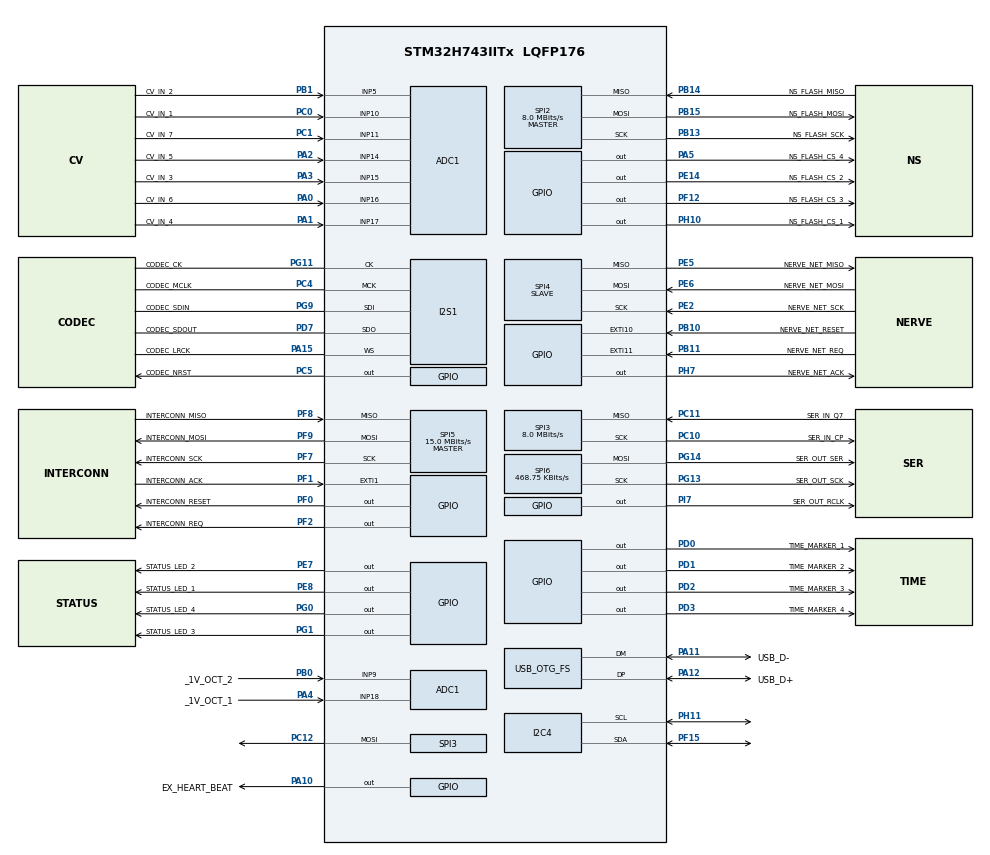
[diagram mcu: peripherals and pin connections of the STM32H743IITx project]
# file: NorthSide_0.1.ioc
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ADC1.Channel-10\#ChannelRegularConversion=ADC_CHANNEL_5
ADC1.Channel-11\#ChannelRegularConversion=ADC_CHANNEL_15
ADC1.Channel-12\#ChannelRegularConversion=ADC_CHANNEL_17
ADC1.Channel-13\#ChannelRegularConversion=ADC_CHANNEL_14
ADC1.Channel-14\#ChannelRegularConversion=ADC_CHANNEL_16
ADC1.Channel-16\#ChannelRegularConversion=ADC_CHANNEL_11
ADC1.Channel-7\#ChannelRegularConversion=ADC_CHANNEL_18
ADC1.Channel-8\#ChannelRegularConversion=ADC_CHANNEL_9
ADC1.Channel-9\#ChannelRegularConversion=ADC_CHANNEL_10
ADC1.ClockPrescaler=ADC_CLOCK_ASYNC_DIV8
ADC1.NbrOfConversion=9
ADC1.NbrOfConversionFlag=1
ADC1.OffsetNumber-10\#ChannelRegularConversion=ADC_OFFSET_NONE
ADC1.OffsetNumber-11\#ChannelRegularConversion=ADC_OFFSET_NONE
ADC1.OffsetNumber-12\#ChannelRegularConversion=ADC_OFFSET_NONE
ADC1.OffsetNumber-13\#ChannelRegularConversion=ADC_OFFSET_NONE
ADC1.OffsetNumber-14\#ChannelRegularConversion=ADC_OFFSET_NONE
ADC1.OffsetNumber-16\#ChannelRegularConversion=ADC_OFFSET_NONE
ADC1.OffsetNumber-7\#ChannelRegularConversion=ADC_OFFSET_NONE
ADC1.OffsetNumber-8\#ChannelRegularConversion=ADC_OFFSET_NONE
ADC1.OffsetNumber-9\#ChannelRegularConversion=ADC_OFFSET_NONE
ADC1.OffsetSignedSaturation-10\#ChannelRegularConversion=DISABLE
ADC1.OffsetSignedSaturation-11\#ChannelRegularConversion=DISABLE
ADC1.OffsetSignedSaturation-12\#ChannelRegularConversion=DISABLE
ADC1.OffsetSignedSaturation-13\#ChannelRegularConversion=DISABLE
ADC1.OffsetSignedSaturation-14\#ChannelRegularConversion=DISABLE
ADC1.OffsetSignedSaturation-16\#ChannelRegularConversion=DISABLE
ADC1.OffsetSignedSaturation-7\#ChannelRegularConversion=DISABLE
ADC1.OffsetSignedSaturation-8\#ChannelRegularConversion=DISABLE
ADC1.OffsetSignedSaturation-9\#ChannelRegularConversion=DISABLE
ADC1.Rank-10\#ChannelRegularConversion=4
ADC1.Rank-11\#ChannelRegularConversion=5
ADC1.Rank-12\#ChannelRegularConversion=6
ADC1.Rank-13\#ChannelRegularConversion=7
ADC1.Rank-14\#ChannelRegularConversion=8
ADC1.Rank-16\#ChannelRegularConversion=9
ADC1.Rank-7\#ChannelRegularConversion=1
ADC1.Rank-8\#ChannelRegularConversion=2
ADC1.Rank-9\#ChannelRegularConversion=3
ADC1.SamplingTime-10\#ChannelRegularConversion=ADC_SAMPLETIME_16CYCLES_5
ADC1.SamplingTime-11\#ChannelRegularConversion=ADC_SAMPLETIME_16CYCLES_5
ADC1.SamplingTime-12\#ChannelRegularConversion=ADC_SAMPLETIME_16CYCLES_5
ADC1.SamplingTime-13\#ChannelRegularConversion=ADC_SAMPLETIME_16CYCLES_5
ADC1.SamplingTime-14\#ChannelRegularConversion=ADC_SAMPLETIME_16CYCLES_5
ADC1.SamplingTime-16\#ChannelRegularConversion=ADC_SAMPLETIME_16CYCLES_5
ADC1.SamplingTime-7\#ChannelRegularConversion=ADC_SAMPLETIME_16CYCLES_5
ADC1.SamplingTime-8\#ChannelRegularConversion=ADC_SAMPLETIME_16CYCLES_5
ADC1.SamplingTime-9\#ChannelRegularConversion=ADC_SAMPLETIME_16CYCLES_5
ADC1.master=1
Bdma.Request0=SPI6_TX
Bdma.RequestsNb=1
Bdma.SPI6_TX.0.Direction=DMA_MEMORY_TO_PERIPH
Bdma.SPI6_TX.0.EventEnable=DISABLE
Bdma.SPI6_TX.0.Instance=BDMA_Channel0
Bdma.SPI6_TX.0.MemDataAlignment=DMA_MDATAALIGN_BYTE
Bdma.SPI6_TX.0.MemInc=DMA_MINC_ENABLE
Bdma.SPI6_TX.0.Mode=DMA_NORMAL
Bdma.SPI6_TX.0.PeriphDataAlignment=DMA_PDATAALIGN_BYTE
Bdma.SPI6_TX.0.PeriphInc=DMA_PINC_DISABLE
Bdma.SPI6_TX.0.Polarity=HAL_DMAMUX_REQ_GEN_RISING
Bdma.SPI6_TX.0.Priority=DMA_PRIORITY_LOW
Bdma.SPI6_TX.0.RequestNumber=1
Bdma.SPI6_TX.0.SignalID=NONE
Bdma.SPI6_TX.0.SyncEnable=DISABLE
Bdma.SPI6_TX.0.SyncPolarity=HAL_DMAMUX_SYNC_NO_EVENT
Bdma.SPI6_TX.0.SyncRequestNumber=1
Bdma.SPI6_TX.0.SyncSignalID=NONE
CORTEX_M7.AccessPermission_Spec=MPU_REGION_FULL_ACCESS
CORTEX_M7.BaseAddress_Spec=0x30000000
CORTEX_M7.CPU_DCache=Disabled
CORTEX_M7.CPU_ICache=Disabled
CORTEX_M7.Size_Spec=MPU_REGION_SIZE_256KB
CORTEX_M7.default_mode_Activation=1
Dma.ADC1.4.Direction=DMA_PERIPH_TO_MEMORY
Dma.ADC1.4.EventEnable=DISABLE
Dma.ADC1.4.FIFOMode=DMA_FIFOMODE_DISABLE
Dma.ADC1.4.Instance=DMA1_Stream2
Dma.ADC1.4.MemDataAlignment=DMA_MDATAALIGN_HALFWORD
Dma.ADC1.4.MemInc=DMA_MINC_ENABLE
Dma.ADC1.4.Mode=DMA_NORMAL
Dma.ADC1.4.PeriphDataAlignment=DMA_PDATAALIGN_HALFWORD
Dma.ADC1.4.PeriphInc=DMA_PINC_DISABLE
Dma.ADC1.4.Polarity=HAL_DMAMUX_REQ_GEN_RISING
Dma.ADC1.4.Priority=DMA_PRIORITY_LOW
Dma.ADC1.4.RequestNumber=1
Dma.ADC1.4.SignalID=NONE
Dma.ADC1.4.SyncEnable=DISABLE
Dma.ADC1.4.SyncPolarity=HAL_DMAMUX_SYNC_NO_EVENT
Dma.ADC1.4.SyncRequestNumber=1
Dma.ADC1.4.SyncSignalID=NONE
Dma.Request0=SPI5_RX
Dma.Request1=SPI5_TX
Dma.Request2=SPI1_RX
Dma.Request3=SPI1_TX
Dma.Request4=ADC1
Dma.Request5=SPI4_RX
Dma.Request6=SPI4_TX
Dma.SPI1_RX.2.Direction=DMA_PERIPH_TO_MEMORY
Dma.SPI1_RX.2.EventEnable=DISABLE
Dma.SPI1_RX.2.FIFOMode=DMA_FIFOMODE_DISABLE
Dma.SPI1_RX.2.Instance=DMA1_Stream3
Dma.SPI1_RX.2.MemDataAlignment=DMA_MDATAALIGN_WORD
Dma.SPI1_RX.2.MemInc=DMA_MINC_ENABLE
Dma.SPI1_RX.2.Mode=DMA_CIRCULAR
Dma.SPI1_RX.2.PeriphDataAlignment=DMA_PDATAALIGN_WORD
Dma.SPI1_RX.2.PeriphInc=DMA_PINC_DISABLE
Dma.SPI1_RX.2.Polarity=HAL_DMAMUX_REQ_GEN_RISING
Dma.SPI1_RX.2.Priority=DMA_PRIORITY_LOW
Dma.SPI1_RX.2.RequestNumber=1
Dma.SPI1_RX.2.SignalID=NONE
Dma.SPI1_RX.2.SyncEnable=DISABLE
Dma.SPI1_RX.2.SyncPolarity=HAL_DMAMUX_SYNC_NO_EVENT
Dma.SPI1_RX.2.SyncRequestNumber=1
Dma.SPI1_RX.2.SyncSignalID=NONE
Dma.SPI1_TX.3.Direction=DMA_MEMORY_TO_PERIPH
Dma.SPI1_TX.3.EventEnable=DISABLE
Dma.SPI1_TX.3.FIFOMode=DMA_FIFOMODE_DISABLE
Dma.SPI1_TX.3.Instance=DMA1_Stream4
Dma.SPI1_TX.3.MemDataAlignment=DMA_MDATAALIGN_WORD
Dma.SPI1_TX.3.MemInc=DMA_MINC_ENABLE
Dma.SPI1_TX.3.Mode=DMA_CIRCULAR
Dma.SPI1_TX.3.PeriphDataAlignment=DMA_PDATAALIGN_WORD
Dma.SPI1_TX.3.PeriphInc=DMA_PINC_DISABLE
Dma.SPI1_TX.3.Polarity=HAL_DMAMUX_REQ_GEN_RISING
Dma.SPI1_TX.3.Priority=DMA_PRIORITY_LOW
Dma.SPI1_TX.3.RequestNumber=1
Dma.SPI1_TX.3.SignalID=NONE
Dma.SPI1_TX.3.SyncEnable=DISABLE
Dma.SPI1_TX.3.SyncPolarity=HAL_DMAMUX_SYNC_NO_EVENT
Dma.SPI1_TX.3.SyncRequestNumber=1
Dma.SPI1_TX.3.SyncSignalID=NONE
Dma.SPI4_RX.5.Direction=DMA_PERIPH_TO_MEMORY
Dma.SPI4_RX.5.EventEnable=DISABLE
Dma.SPI4_RX.5.FIFOMode=DMA_FIFOMODE_DISABLE
Dma.SPI4_RX.5.Instance=DMA1_Stream5
Dma.SPI4_RX.5.MemDataAlignment=DMA_MDATAALIGN_BYTE
Dma.SPI4_RX.5.MemInc=DMA_MINC_ENABLE
Dma.SPI4_RX.5.Mode=DMA_NORMAL
Dma.SPI4_RX.5.PeriphDataAlignment=DMA_PDATAALIGN_BYTE
Dma.SPI4_RX.5.PeriphInc=DMA_PINC_DISABLE
Dma.SPI4_RX.5.Polarity=HAL_DMAMUX_REQ_GEN_RISING
Dma.SPI4_RX.5.Priority=DMA_PRIORITY_LOW
Dma.SPI4_RX.5.RequestNumber=1
Dma.SPI4_RX.5.SignalID=NONE
Dma.SPI4_RX.5.SyncEnable=DISABLE
Dma.SPI4_RX.5.SyncPolarity=HAL_DMAMUX_SYNC_NO_EVENT
Dma.SPI4_RX.5.SyncRequestNumber=1
Dma.SPI4_RX.5.SyncSignalID=NONE
Dma.SPI4_TX.6.Direction=DMA_MEMORY_TO_PERIPH
Dma.SPI4_TX.6.EventEnable=DISABLE
Dma.SPI4_TX.6.FIFOMode=DMA_FIFOMODE_DISABLE
Dma.SPI4_TX.6.Instance=DMA1_Stream6
Dma.SPI4_TX.6.MemDataAlignment=DMA_MDATAALIGN_BYTE
Dma.SPI4_TX.6.MemInc=DMA_MINC_ENABLE
Dma.SPI4_TX.6.Mode=DMA_NORMAL
Dma.SPI4_TX.6.PeriphDataAlignment=DMA_PDATAALIGN_BYTE
Dma.SPI4_TX.6.PeriphInc=DMA_PINC_DISABLE
Dma.SPI4_TX.6.Polarity=HAL_DMAMUX_REQ_GEN_RISING
Dma.SPI4_TX.6.Priority=DMA_PRIORITY_LOW
Dma.SPI4_TX.6.RequestNumber=1
Dma.SPI4_TX.6.SignalID=NONE
Dma.SPI4_TX.6.SyncEnable=DISABLE
Dma.SPI4_TX.6.SyncPolarity=HAL_DMAMUX_SYNC_NO_EVENT
Dma.SPI4_TX.6.SyncRequestNumber=1
Dma.SPI4_TX.6.SyncSignalID=NONE
Dma.SPI5_RX.0.Direction=DMA_PERIPH_TO_MEMORY
Dma.SPI5_RX.0.EventEnable=DISABLE
Dma.SPI5_RX.0.FIFOMode=DMA_FIFOMODE_DISABLE
Dma.SPI5_RX.0.Instance=DMA1_Stream0
Dma.SPI5_RX.0.MemDataAlignment=DMA_MDATAALIGN_BYTE
Dma.SPI5_RX.0.MemInc=DMA_MINC_ENABLE
Dma.SPI5_RX.0.Mode=DMA_NORMAL
Dma.SPI5_RX.0.PeriphDataAlignment=DMA_PDATAALIGN_BYTE
Dma.SPI5_RX.0.PeriphInc=DMA_PINC_DISABLE
Dma.SPI5_RX.0.Polarity=HAL_DMAMUX_REQ_GEN_RISING
Dma.SPI5_RX.0.Priority=DMA_PRIORITY_LOW
Dma.SPI5_RX.0.RequestNumber=1
Dma.SPI5_RX.0.SignalID=NONE
Dma.SPI5_RX.0.SyncEnable=DISABLE
Dma.SPI5_RX.0.SyncPolarity=HAL_DMAMUX_SYNC_NO_EVENT
Dma.SPI5_RX.0.SyncRequestNumber=1
Dma.SPI5_RX.0.SyncSignalID=NONE
Dma.SPI5_TX.1.Direction=DMA_MEMORY_TO_PERIPH
Dma.SPI5_TX.1.EventEnable=DISABLE
Dma.SPI5_TX.1.FIFOMode=DMA_FIFOMODE_DISABLE
Dma.SPI5_TX.1.Instance=DMA1_Stream1
Dma.SPI5_TX.1.MemDataAlignment=DMA_MDATAALIGN_BYTE
Dma.SPI5_TX.1.MemInc=DMA_MINC_ENABLE
Dma.SPI5_TX.1.Mode=DMA_NORMAL
Dma.SPI5_TX.1.PeriphDataAlignment=DMA_PDATAALIGN_BYTE
Dma.SPI5_TX.1.PeriphInc=DMA_PINC_DISABLE
Dma.SPI5_TX.1.Polarity=HAL_DMAMUX_REQ_GEN_RISING
Dma.SPI5_TX.1.Priority=DMA_PRIORITY_LOW
Dma.SPI5_TX.1.RequestNumber=1
Dma.SPI5_TX.1.SignalID=NONE
Dma.SPI5_TX.1.SyncEnable=DISABLE
Dma.SPI5_TX.1.SyncPolarity=HAL_DMAMUX_SYNC_NO_EVENT
Dma.SPI5_TX.1.SyncRequestNumber=1
Dma.SPI5_TX.1.SyncSignalID=NONE
FREERTOS.Tasks01=defaultTask,24,128,StartDefaultTask,Default,NULL,Dynamic,NULL,NULL
FREERTOS.configENABLE_FPU=1
FREERTOS.configTOTAL_HEAP_SIZE=43008
FREERTOS.configUSE_NEWLIB_REENTRANT=1
I2C4.Speed=20
I2C4.Timing=0xF01075FF
I2S1.AudioFreq=I2S_AUDIOFREQ_44K
I2S1.Data24BitAlignment=I2S_DATA_24BIT_ALIGNMENT_LEFT
I2S1.DataFormat=I2S_DATAFORMAT_24B
I2S1.ErrorAudioFreq=-5.3 %
I2S1.Instance=SPI$Index
I2S1.RealAudioFreq=41.666 KHz
Mcu.Family=STM32H7
Mcu.Name=STM32H743IITx
Mcu.Package=LQFP176
NVIC.BDMA_Channel0_IRQn=true\:5\:0\:false\:false\:true\:true\:false\:true\:true
NVIC.DMA1_Stream0_IRQn=true\:5\:0\:false\:false\:true\:true\:false\:true\:true
NVIC.DMA1_Stream1_IRQn=true\:5\:0\:false\:false\:true\:true\:false\:true\:true
NVIC.DMA1_Stream2_IRQn=true\:5\:0\:false\:false\:true\:true\:false\:true\:true
NVIC.DMA1_Stream3_IRQn=true\:5\:0\:false\:false\:true\:true\:false\:true\:true
NVIC.DMA1_Stream4_IRQn=true\:5\:0\:false\:false\:true\:true\:false\:true\:true
NVIC.DMA1_Stream5_IRQn=true\:5\:0\:false\:false\:true\:true\:false\:true\:true
NVIC.DMA1_Stream6_IRQn=true\:5\:0\:false\:false\:true\:true\:false\:true\:true
NVIC.EXTI15_10_IRQn=true\:5\:0\:false\:false\:true\:true\:true\:true\:true
NVIC.EXTI1_IRQn=true\:5\:0\:false\:false\:true\:true\:true\:true\:true
NVIC.PriorityGroup=NVIC_PRIORITYGROUP_4
NVIC.SPI4_IRQn=true\:5\:0\:false\:false\:true\:true\:false\:true\:true
NVIC.SPI5_IRQn=true\:5\:0\:false\:false\:true\:true\:false\:true\:true
NVIC.SPI6_IRQn=true\:5\:0\:false\:false\:true\:true\:false\:true\:true
NVIC.TIM15_IRQn=true\:5\:0\:false\:false\:true\:true\:true\:true\:true
NVIC.TIM1_UP_IRQn=true\:15\:0\:false\:false\:true\:false\:false\:true\:true
NVIC.TIM8_BRK_TIM12_IRQn=true\:5\:0\:false\:false\:true\:true\:true\:true\:true
NVIC.TimeBase=TIM1_UP_IRQn
NVIC.TimeBaseIP=TIM1
PA0.GPIO_Label=CV_IN_6
PA0.Mode=IN16-Single-Ended
PA0.Signal=ADC1_INP16
PA1.GPIO_Label=CV_IN_4
PA1.Mode=IN17-Single-Ended
PA1.Signal=ADC1_INP17
PA10.GPIO_Label=EX_HEART_BEAT
PA10.GPIO_ModeDefaultOutputPP=GPIO_MODE_OUTPUT_OD
PA10.GPIO_PuPd=GPIO_NOPULL
PA10.PinState=GPIO_PIN_SET
PA10.Signal=GPIO_Output
PA11.GPIO_Label=USB_D-
PA11.Mode=Device_Only
PA11.Signal=USB_OTG_FS_DM
PA12.GPIO_Label=USB_D+
PA12.Mode=Device_Only
PA12.Signal=USB_OTG_FS_DP
PA13\ (JTMS/SWDIO).Mode=Serial_Wire
PA13\ (JTMS/SWDIO).Signal=DEBUG_JTMS-SWDIO
PA14\ (JTCK/SWCLK).Mode=Serial_Wire
PA14\ (JTCK/SWCLK).Signal=DEBUG_JTCK-SWCLK
PA15\ (JTDI).GPIO_Label=CODEC_LRCK
PA15\ (JTDI).Mode=Full_Duplex_Master
PA15\ (JTDI).Signal=I2S1_WS
PA2.GPIO_Label=CV_IN_5
PA2.Signal=ADCx_INP14
PA3.GPIO_Label=CV_IN_3
PA3.Signal=ADCx_INP15
PA4.GPIO_Label=_1V_OCT_1
PA4.Signal=ADCx_INP18
PA5.GPIO_Label=NS_FLASH_CS_4
PA5.GPIO_Speed=GPIO_SPEED_FREQ_MEDIUM
PA5.PinState=GPIO_PIN_SET
PA5.Signal=GPIO_Output
PB0.GPIO_Label=_1V_OCT_2
PB0.Signal=ADCx_INP9
PB1.GPIO_Label=CV_IN_2
PB1.Signal=ADCx_INP5
PB10.GPIO_Label=NERVE_NET_RESET
PB10.GPIO_ModeDefaultEXTI=GPIO_MODE_IT_RISING_FALLING
PB10.Signal=GPXTI10
PB11.GPIO_Label=NERVE_NET_REQ
PB11.GPIO_ModeDefaultEXTI=GPIO_MODE_IT_RISING_FALLING
PB11.Signal=GPXTI11
PB13.GPIO_Label=NS_FLASH_SCK
PB13.Mode=Full_Duplex_Master
PB13.Signal=SPI2_SCK
PB14.GPIO_Label=NS_FLASH_MISO
PB14.Mode=Full_Duplex_Master
PB14.Signal=SPI2_MISO
PB15.GPIO_Label=NS_FLASH_MOSI
PB15.Mode=Full_Duplex_Master
PB15.Signal=SPI2_MOSI
PC0.GPIO_Label=CV_IN_1
PC0.Signal=ADCx_INP10
PC1.GPIO_Label=CV_IN_7
PC1.Signal=ADCx_INP11
PC10.GPIO_Label=SER_IN_CP
PC10.Mode=Full_Duplex_Master
PC10.Signal=SPI3_SCK
PC11.GPIO_Label=SER_IN_Q7
PC11.Mode=Full_Duplex_Master
PC11.Signal=SPI3_MISO
PC12.Mode=Full_Duplex_Master
PC12.Signal=SPI3_MOSI
PC4.GPIO_Label=CODEC_MCLK
PC4.Mode=Master_Clock_Activated
PC4.Signal=I2S1_MCK
PC5.GPIO_Label=CODEC_NRST
PC5.GPIO_PuPd=GPIO_PULLUP
PC5.GPIO_Speed=GPIO_SPEED_FREQ_MEDIUM
PC5.PinState=GPIO_PIN_SET
PC5.Signal=GPIO_Output
PD0.GPIO_Label=TIME_MARKER_1
PD0.GPIO_Speed=GPIO_SPEED_FREQ_HIGH
PD0.PinState=GPIO_PIN_RESET
PD0.Signal=GPIO_Output
PD1.GPIO_Label=TIME_MARKER_2
PD1.GPIO_Speed=GPIO_SPEED_FREQ_HIGH
PD1.PinState=GPIO_PIN_RESET
PD1.Signal=GPIO_Output
PD2.GPIO_Label=TIME_MARKER_3
PD2.Signal=GPIO_Output
PD3.GPIO_Label=TIME_MARKER_4
PD3.GPIO_Speed=GPIO_SPEED_FREQ_HIGH
PD3.PinState=GPIO_PIN_RESET
PD3.Signal=GPIO_Output
PD7.GPIO_Label=CODEC_SDOUT
PD7.Mode=Full_Duplex_Master
PD7.Signal=I2S1_SDO
PE14.GPIO_Label=NS_FLASH_CS_2
PE14.GPIO_Speed=GPIO_SPEED_FREQ_MEDIUM
PE14.PinState=GPIO_PIN_SET
PE14.Signal=GPIO_Output
PE2.GPIO_Label=NERVE_NET_SCK
PE2.Mode=Full_Duplex_Slave
PE2.Signal=SPI4_SCK
PE5.GPIO_Label=NERVE_NET_MISO
PE5.Mode=Full_Duplex_Slave
PE5.Signal=SPI4_MISO
PE6.GPIO_Label=NERVE_NET_MOSI
PE6.Mode=Full_Duplex_Slave
PE6.Signal=SPI4_MOSI
PE7.GPIO_Label=STATUS_LED_2
PE7.GPIO_ModeDefaultOutputPP=GPIO_MODE_OUTPUT_OD
PE7.GPIO_PuPd=GPIO_NOPULL
PE7.GPIO_Speed=GPIO_SPEED_FREQ_LOW
PE7.PinState=GPIO_PIN_SET
PE7.Signal=GPIO_Output
PE8.GPIO_Label=STATUS_LED_1
PE8.GPIO_ModeDefaultOutputPP=GPIO_MODE_OUTPUT_OD
PE8.GPIO_PuPd=GPIO_NOPULL
PE8.PinState=GPIO_PIN_SET
PE8.Signal=GPIO_Output
PF0.GPIO_Label=INTERCONN_RESET
PF0.GPIO_PuPd=GPIO_PULLUP
PF0.GPIO_Speed=GPIO_SPEED_FREQ_MEDIUM
PF0.PinState=GPIO_PIN_RESET
PF0.Signal=GPIO_Output
PF1.GPIO_Label=INTERCONN_ACK
PF1.GPIO_ModeDefaultEXTI=GPIO_MODE_IT_RISING_FALLING
PF1.Signal=GPXTI1
PF12.GPIO_Label=NS_FLASH_CS_3
PF12.GPIO_Speed=GPIO_SPEED_FREQ_MEDIUM
PF12.PinState=GPIO_PIN_SET
PF12.Signal=GPIO_Output
PF15.Mode=I2C
PF15.Signal=I2C4_SDA
PF2.GPIO_Label=INTERCONN_REQ
PF2.GPIO_PuPd=GPIO_PULLUP
PF2.GPIO_Speed=GPIO_SPEED_FREQ_MEDIUM
PF2.PinState=GPIO_PIN_RESET
PF2.Signal=GPIO_Output
PF7.GPIO_Label=INTERCONN_SCK
PF7.Mode=Full_Duplex_Master
PF7.Signal=SPI5_SCK
PF8.GPIO_Label=INTERCONN_MISO
PF8.Mode=Full_Duplex_Master
PF8.Signal=SPI5_MISO
PF9.GPIO_Label=INTERCONN_MOSI
PF9.Mode=Full_Duplex_Master
PF9.Signal=SPI5_MOSI
PG0.GPIO_Label=STATUS_LED_4
PG0.GPIO_ModeDefaultOutputPP=GPIO_MODE_OUTPUT_OD
PG0.GPIO_PuPd=GPIO_NOPULL
PG0.PinState=GPIO_PIN_SET
PG0.Signal=GPIO_Output
PG1.GPIO_Label=STATUS_LED_3
PG1.GPIO_ModeDefaultOutputPP=GPIO_MODE_OUTPUT_OD
PG1.GPIO_PuPd=GPIO_NOPULL
PG1.PinState=GPIO_PIN_SET
PG1.Signal=GPIO_Output
PG11.GPIO_Label=CODEC_CK
PG11.Mode=Full_Duplex_Master
PG11.Signal=I2S1_CK
PG12.Signal=SPI6_MISO
PG13.GPIO_Label=SER_OUT_SCK
PG13.Mode=TX_Only_Simplex_Unidirect_Master
PG13.Signal=SPI6_SCK
PG14.GPIO_Label=SER_OUT_SER
PG14.Mode=TX_Only_Simplex_Unidirect_Master
PG14.Signal=SPI6_MOSI
PG9.GPIO_Label=CODEC_SDIN
PG9.Mode=Full_Duplex_Master
PG9.Signal=I2S1_SDI
PH0-OSC_IN\ (PH0).Mode=HSE-External-Oscillator
PH0-OSC_IN\ (PH0).Signal=RCC_OSC_IN
PH1-OSC_OUT\ (PH1).Mode=HSE-External-Oscillator
PH1-OSC_OUT\ (PH1).Signal=RCC_OSC_OUT
PH10.GPIO_Label=NS_FLASH_CS_1
PH10.GPIO_ModeDefaultOutputPP=GPIO_MODE_OUTPUT_PP
PH10.GPIO_Speed=GPIO_SPEED_FREQ_MEDIUM
PH10.PinState=GPIO_PIN_SET
PH10.Signal=GPIO_Output
PH11.Mode=I2C
PH11.Signal=I2C4_SCL
PH7.GPIO_Label=NERVE_NET_ACK
PH7.GPIO_Speed=GPIO_SPEED_FREQ_MEDIUM
PH7.Signal=GPIO_Output
PI7.GPIO_Label=SER_OUT_RCLK
PI7.Signal=GPIO_Output
ProjectManager.HeapSize=0x200
ProjectManager.StackSize=0x400
ProjectManager.TargetToolchain=STM32CubeIDE
RCC.ADCFreq_Value=75000000
RCC.APB1Freq_Value=120000000
RCC.APB2Freq_Value=120000000
RCC.APB3Freq_Value=120000000
RCC.APB4Freq_Value=120000000
RCC.CortexFreq_Value=480000000
RCC.D1PPRE=RCC_APB3_DIV2
RCC.D2PPRE1=RCC_APB1_DIV2
RCC.D2PPRE2=RCC_APB2_DIV2
RCC.D3PPRE=RCC_APB4_DIV2
RCC.DIVM1=5
RCC.DIVM2=2
RCC.DIVN1=192
RCC.DIVN2=12
RCC.DIVQ1=15
RCC.HCLKFreq_Value=240000000
RCC.HPRE=RCC_HCLK_DIV2
RCC.HSE_VALUE=25000000
RCC.PLL2FRACN=0
RCC.PLL3FRACN=0
RCC.PLLFRACN=0
RCC.SYSCLKFreq_VALUE=480000000
RCC.SYSCLKSource=RCC_SYSCLKSOURCE_PLLCLK
RCC.USBFreq_Value=64000000
SH.ADCx_INP10.0=ADC1_INP10,IN10-Single-Ended
SH.ADCx_INP11.0=ADC1_INP11,IN11-Single-Ended
SH.ADCx_INP14.0=ADC1_INP14,IN14-Single-Ended
SH.ADCx_INP15.0=ADC1_INP15,IN15-Single-Ended
SH.ADCx_INP18.0=ADC1_INP18,IN18-Single-Ended
SH.ADCx_INP5.0=ADC1_INP5,IN5-Single-Ended
SH.ADCx_INP9.0=ADC1_INP9,IN9-Single-Ended
SPI2.BaudRatePrescaler=SPI_BAUDRATEPRESCALER_8
SPI2.CalculateBaudRate=8.0 MBits/s
SPI2.DataSize=SPI_DATASIZE_8BIT
SPI2.Direction=SPI_DIRECTION_2LINES
SPI2.Mode=SPI_MODE_MASTER
SPI2.VirtualType=VM_MASTER
SPI3.BaudRatePrescaler=SPI_BAUDRATEPRESCALER_8
SPI3.CalculateBaudRate=8.0 MBits/s
SPI3.DataSize=SPI_DATASIZE_8BIT
SPI3.Direction=SPI_DIRECTION_2LINES
SPI3.Mode=SPI_MODE_MASTER
SPI3.VirtualType=VM_MASTER
SPI4.DataSize=SPI_DATASIZE_8BIT
SPI4.Direction=SPI_DIRECTION_2LINES
SPI4.Mode=SPI_MODE_SLAVE
SPI4.VirtualType=VM_SLAVE
SPI5.BaudRatePrescaler=SPI_BAUDRATEPRESCALER_8
SPI5.CalculateBaudRate=15.0 MBits/s
SPI5.DataSize=SPI_DATASIZE_8BIT
SPI5.Direction=SPI_DIRECTION_2LINES
SPI5.Mode=SPI_MODE_MASTER
SPI5.VirtualType=VM_MASTER
SPI6.BaudRatePrescaler=SPI_BAUDRATEPRESCALER_256
SPI6.CalculateBaudRate=468.75 KBits/s
SPI6.DataSize=SPI_DATASIZE_8BIT
SPI6.Direction=SPI_DIRECTION_2LINES_TXONLY
SPI6.FirstBit=SPI_FIRSTBIT_MSB
SPI6.Mode=SPI_MODE_MASTER
SPI6.VirtualType=VM_MASTER
TIM15.Period=100 - 1
TIM15.Prescaler=24000 - 1
TIM2.Period=1000-1
TIM2.Prescaler=240-1
TIM2.TIM_MasterOutputTrigger=TIM_TRGO_UPDATE
TIM8.Period=20-1
TIM8.Prescaler=240 - 1
TIM8.TIM_MasterOutputTrigger=TIM_TRGO_UPDATE
USB_OTG_FS.VirtualMode=Device_Only
VP_FREERTOS_VS_CMSIS_V2.Mode=CMSIS_V2
VP_MEMORYMAP_VS_MEMORYMAP.Mode=CurAppReg
VP_SYS_VS_tim1.Mode=TIM1
VP_TIM15_VS_ClockSourceINT.Mode=Internal
VP_TIM2_VS_ClockSourceINT.Mode=Internal
VP_TIM8_VS_ClockSourceINT.Mode=Internal
board=custom

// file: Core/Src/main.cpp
/* USER CODE BEGIN Header */

/****  NorthSide ****/

/**
  ******************************************************************************
  * @file           : main.c
  * @brief          : Main program body
  ******************************************************************************
  * @attention
  *
  * Copyright (c) 2024 STMicroelectronics.
  * All rights reserved.
  *
  * This software is licensed under terms that can be found in the LICENSE file
  * in the root directory of this software component.
  * If no LICENSE file comes with this software, it is provided AS-IS.
  *
  ******************************************************************************
  */
/* USER CODE END Header */
#include "main.h"
#include "cmsis_os.h"

/* USER CODE BEGIN Includes */

#include "string.h"

#include "CasualNoises.h"

#include "YellowPages.h"

#include "NorthSideEngine.h"
#include "NorthSideAudioProcessor.h"
#include "DeviceBoardConnection.h"

#include "EventHandlerThread.h"

#include <NerveNet/NerveNetMessage.h>

/* USER CODE END Includes */

ADC_HandleTypeDef hadc1;
DMA_HandleTypeDef hdma_adc1;

I2C_HandleTypeDef hi2c4;

I2S_HandleTypeDef hi2s1;
DMA_HandleTypeDef hdma_spi1_rx;
DMA_HandleTypeDef hdma_spi1_tx;

SPI_HandleTypeDef hspi2;
SPI_HandleTypeDef hspi3;
SPI_HandleTypeDef hspi4;
SPI_HandleTypeDef hspi5;
SPI_HandleTypeDef hspi6;
DMA_HandleTypeDef hdma_spi4_rx;
DMA_HandleTypeDef hdma_spi4_tx;
DMA_HandleTypeDef hdma_spi5_rx;
DMA_HandleTypeDef hdma_spi5_tx;
DMA_HandleTypeDef hdma_spi6_tx;

TIM_HandleTypeDef htim2;
TIM_HandleTypeDef htim8;
TIM_HandleTypeDef htim15;

PCD_HandleTypeDef hpcd_USB_OTG_FS;

/* Definitions for defaultTask */
osThreadId_t defaultTaskHandle;
const osThreadAttr_t defaultTask_attributes = {
  .name = "defaultTask",
  .stack_size = 128 * 4,
  .priority = (osPriority_t) osPriorityNormal,
};

void SystemClock_Config(void);
static void MPU_Config(void);
static void MX_GPIO_Init(void);
static void MX_DMA_Init(void);
static void MX_BDMA_Init(void);
static void MX_USB_OTG_FS_PCD_Init(void);
static void MX_SPI2_Init(void);
static void MX_SPI3_Init(void);
static void MX_SPI4_Init(void);
static void MX_SPI5_Init(void);
static void MX_SPI6_Init(void);
static void MX_ADC1_Init(void);
static void MX_I2S1_Init(void);
static void MX_TIM2_Init(void);
static void MX_I2C4_Init(void);
static void MX_TIM8_Init(void);
static void MX_TIM15_Init(void);
void StartDefaultTask(void *argument);

/* USER CODE BEGIN 0 */

/*
 * displayStatus()
 */
void displayStatus(eStatusCodes status)
{
	uint32_t code = (uint32_t)status;
	HAL_GPIO_WritePin(GPIOE, STATUS_LED_2_Pin|STATUS_LED_1_Pin, GPIO_PIN_SET);
	HAL_GPIO_WritePin(GPIOG, STATUS_LED_4_Pin|STATUS_LED_3_Pin, GPIO_PIN_SET);
	if (code & 0x00000001)
		HAL_GPIO_WritePin(GPIOE, STATUS_LED_1_Pin, GPIO_PIN_RESET);
	if (code & 0x00000002)
		HAL_GPIO_WritePin(GPIOE, STATUS_LED_2_Pin, GPIO_PIN_RESET);
	if (code & 0x00000004)
		HAL_GPIO_WritePin(GPIOG, STATUS_LED_3_Pin, GPIO_PIN_RESET);
	if (code & 0x00000008)
		HAL_GPIO_WritePin(GPIOG, STATUS_LED_4_Pin, GPIO_PIN_RESET);
}

/*
 * Time marker functions used for performance measurement using a logic analyzer
 */
void toggleTimeMarker_1()
{
	HAL_GPIO_TogglePin(GPIOD, TIME_MARKER_1_Pin);
}

void setTimeMarker_1()
{
	HAL_GPIO_WritePin(GPIOD, TIME_MARKER_1_Pin, GPIO_PIN_SET);
}

void resetTimeMarker_1()
{
	HAL_GPIO_WritePin(GPIOD, TIME_MARKER_1_Pin, GPIO_PIN_RESET);
}

void toggleTimeMarker_2()
{
	HAL_GPIO_TogglePin(GPIOD, TIME_MARKER_2_Pin);
}

void setTimeMarker_2()
{
	HAL_GPIO_WritePin(GPIOD, TIME_MARKER_2_Pin, GPIO_PIN_SET);
}

void resetTimeMarker_2()
{
	HAL_GPIO_WritePin(GPIOD, TIME_MARKER_2_Pin, GPIO_PIN_RESET);
}

void toggleTimeMarker_3()
{
	HAL_GPIO_TogglePin(GPIOD, TIME_MARKER_3_Pin);
}

void setTimeMarker_3()
{
	HAL_GPIO_WritePin(GPIOD, TIME_MARKER_3_Pin, GPIO_PIN_SET);
}

void resetTimeMarker_3()
{
	HAL_GPIO_WritePin(GPIOD, TIME_MARKER_3_Pin, GPIO_PIN_RESET);
}

void toggleTimeMarker_4()
{
	HAL_GPIO_TogglePin(GPIOD, TIME_MARKER_4_Pin);
}

void setTimeMarker_4()
{
	HAL_GPIO_WritePin(GPIOD, TIME_MARKER_4_Pin, GPIO_PIN_SET);
}

void resetTimeMarker_4()
{
	HAL_GPIO_WritePin(GPIOD, TIME_MARKER_4_Pin, GPIO_PIN_RESET);
}

/* USER CODE END 0 */

int main(void)
{

  /* MPU Configuration--------------------------------------------------------*/
  MPU_Config();

  /* MCU Configuration--------------------------------------------------------*/

  /* Reset of all peripherals, Initializes the Flash interface and the Systick. */
  HAL_Init();

  /* Configure the system clock */
  SystemClock_Config();

  /* Initialize all configured peripherals */
  MX_GPIO_Init();
  MX_DMA_Init();
  MX_BDMA_Init();
  MX_USB_OTG_FS_PCD_Init();
  MX_SPI2_Init();
  MX_SPI3_Init();
  MX_SPI4_Init();
  MX_SPI5_Init();
  MX_SPI6_Init();
  MX_ADC1_Init();
  MX_I2S1_Init();
  MX_TIM2_Init();
  MX_I2C4_Init();
  MX_TIM8_Init();
  MX_TIM15_Init();

  /* Init scheduler */
  osKernelInitialize();

  /* Create the thread(s) */
  /* creation of defaultTask */
  defaultTaskHandle = osThreadNew(StartDefaultTask, NULL, &defaultTask_attributes);

  /* Start scheduler */
  osKernelStart();

  /* We should never get here as control is now taken by the scheduler */

  /* Infinite loop */
  while (1)
  {

  }
}

void SystemClock_Config(void)
{
  RCC_OscInitTypeDef RCC_OscInitStruct = {0};
  RCC_ClkInitTypeDef RCC_ClkInitStruct = {0};

  /** Supply configuration update enable
  */
  HAL_PWREx_ConfigSupply(PWR_LDO_SUPPLY);

  /** Configure the main internal regulator output voltage
  */
  __HAL_PWR_VOLTAGESCALING_CONFIG(PWR_REGULATOR_VOLTAGE_SCALE0);

  while(!__HAL_PWR_GET_FLAG(PWR_FLAG_VOSRDY)) {}

  /** Initializes the RCC Oscillators according to the specified parameters
  * in the RCC_OscInitTypeDef structure.
  */
  RCC_OscInitStruct.OscillatorType = RCC_OSCILLATORTYPE_HSE;
  RCC_OscInitStruct.HSEState = RCC_HSE_ON;
  RCC_OscInitStruct.PLL.PLLState = RCC_PLL_ON;
  RCC_OscInitStruct.PLL.PLLSource = RCC_PLLSOURCE_HSE;
  RCC_OscInitStruct.PLL.PLLM = 5;
  RCC_OscInitStruct.PLL.PLLN = 192;
  RCC_OscInitStruct.PLL.PLLP = 2;
  RCC_OscInitStruct.PLL.PLLQ = 15;
  RCC_OscInitStruct.PLL.PLLR = 2;
  RCC_OscInitStruct.PLL.PLLRGE = RCC_PLL1VCIRANGE_2;
  RCC_OscInitStruct.PLL.PLLVCOSEL = RCC_PLL1VCOWIDE;
  RCC_OscInitStruct.PLL.PLLFRACN = 0;
  if (HAL_RCC_OscConfig(&RCC_OscInitStruct) != HAL_OK)
  {
    Error_Handler();
  }

  /** Initializes the CPU, AHB and APB buses clocks
  */
  RCC_ClkInitStruct.ClockType = RCC_CLOCKTYPE_HCLK|RCC_CLOCKTYPE_SYSCLK
                              |RCC_CLOCKTYPE_PCLK1|RCC_CLOCKTYPE_PCLK2
                              |RCC_CLOCKTYPE_D3PCLK1|RCC_CLOCKTYPE_D1PCLK1;
  RCC_ClkInitStruct.SYSCLKSource = RCC_SYSCLKSOURCE_PLLCLK;
  RCC_ClkInitStruct.SYSCLKDivider = RCC_SYSCLK_DIV1;
  RCC_ClkInitStruct.AHBCLKDivider = RCC_HCLK_DIV2;
  RCC_ClkInitStruct.APB3CLKDivider = RCC_APB3_DIV2;
  RCC_ClkInitStruct.APB1CLKDivider = RCC_APB1_DIV2;
  RCC_ClkInitStruct.APB2CLKDivider = RCC_APB2_DIV2;
  RCC_ClkInitStruct.APB4CLKDivider = RCC_APB4_DIV2;

  if (HAL_RCC_ClockConfig(&RCC_ClkInitStruct, FLASH_LATENCY_4) != HAL_OK)
  {
    Error_Handler();
  }
}

static void MX_ADC1_Init(void)
{

  ADC_MultiModeTypeDef multimode = {0};
  ADC_ChannelConfTypeDef sConfig = {0};

  /** Common config
  */
  hadc1.Instance = ADC1;
  hadc1.Init.ClockPrescaler = ADC_CLOCK_ASYNC_DIV8;
  hadc1.Init.Resolution = ADC_RESOLUTION_16B;
  hadc1.Init.ScanConvMode = ADC_SCAN_ENABLE;
  hadc1.Init.EOCSelection = ADC_EOC_SINGLE_CONV;
  hadc1.Init.LowPowerAutoWait = DISABLE;
  hadc1.Init.ContinuousConvMode = DISABLE;
  hadc1.Init.NbrOfConversion = 9;
  hadc1.Init.DiscontinuousConvMode = DISABLE;
  hadc1.Init.ExternalTrigConv = ADC_SOFTWARE_START;
  hadc1.Init.ExternalTrigConvEdge = ADC_EXTERNALTRIGCONVEDGE_NONE;
  hadc1.Init.ConversionDataManagement = ADC_CONVERSIONDATA_DR;
  hadc1.Init.Overrun = ADC_OVR_DATA_PRESERVED;
  hadc1.Init.LeftBitShift = ADC_LEFTBITSHIFT_NONE;
  hadc1.Init.OversamplingMode = DISABLE;
  hadc1.Init.Oversampling.Ratio = 1;
  if (HAL_ADC_Init(&hadc1) != HAL_OK)
  {
    Error_Handler();
  }

  /** Configure the ADC multi-mode
  */
  multimode.Mode = ADC_MODE_INDEPENDENT;
  if (HAL_ADCEx_MultiModeConfigChannel(&hadc1, &multimode) != HAL_OK)
  {
    Error_Handler();
  }

  /** Configure Regular Channel
  */
  sConfig.Channel = ADC_CHANNEL_18;
  sConfig.Rank = ADC_REGULAR_RANK_1;
  sConfig.SamplingTime = ADC_SAMPLETIME_16CYCLES_5;
  sConfig.SingleDiff = ADC_SINGLE_ENDED;
  sConfig.OffsetNumber = ADC_OFFSET_NONE;
  sConfig.Offset = 0;
  sConfig.OffsetSignedSaturation = DISABLE;
  if (HAL_ADC_ConfigChannel(&hadc1, &sConfig) != HAL_OK)
  {
    Error_Handler();
  }

  /** Configure Regular Channel
  */
  sConfig.Channel = ADC_CHANNEL_9;
  sConfig.Rank = ADC_REGULAR_RANK_2;
  if (HAL_ADC_ConfigChannel(&hadc1, &sConfig) != HAL_OK)
  {
    Error_Handler();
  }

  /** Configure Regular Channel
  */
  sConfig.Channel = ADC_CHANNEL_10;
  sConfig.Rank = ADC_REGULAR_RANK_3;
  if (HAL_ADC_ConfigChannel(&hadc1, &sConfig) != HAL_OK)
  {
    Error_Handler();
  }

  /** Configure Regular Channel
  */
  sConfig.Channel = ADC_CHANNEL_5;
  sConfig.Rank = ADC_REGULAR_RANK_4;
  if (HAL_ADC_ConfigChannel(&hadc1, &sConfig) != HAL_OK)
  {
    Error_Handler();
  }

  /** Configure Regular Channel
  */
  sConfig.Channel = ADC_CHANNEL_15;
  sConfig.Rank = ADC_REGULAR_RANK_5;
  if (HAL_ADC_ConfigChannel(&hadc1, &sConfig) != HAL_OK)
  {
    Error_Handler();
  }

  /** Configure Regular Channel
  */
  sConfig.Channel = ADC_CHANNEL_17;
  sConfig.Rank = ADC_REGULAR_RANK_6;
  if (HAL_ADC_ConfigChannel(&hadc1, &sConfig) != HAL_OK)
  {
    Error_Handler();
  }

  /** Configure Regular Channel
  */
  sConfig.Channel = ADC_CHANNEL_14;
  sConfig.Rank = ADC_REGULAR_RANK_7;
  if (HAL_ADC_ConfigChannel(&hadc1, &sConfig) != HAL_OK)
  {
    Error_Handler();
  }

  /** Configure Regular Channel
  */
  sConfig.Channel = ADC_CHANNEL_16;
  sConfig.Rank = ADC_REGULAR_RANK_8;
  if (HAL_ADC_ConfigChannel(&hadc1, &sConfig) != HAL_OK)
  {
    Error_Handler();
  }

  /** Configure Regular Channel
  */
  sConfig.Channel = ADC_CHANNEL_11;
  sConfig.Rank = ADC_REGULAR_RANK_9;
  if (HAL_ADC_ConfigChannel(&hadc1, &sConfig) != HAL_OK)
  {
    Error_Handler();
  }

}

static void MX_I2C4_Init(void)
{

  hi2c4.Instance = I2C4;
  hi2c4.Init.Timing = 0xF01075FF;
  hi2c4.Init.OwnAddress1 = 0;
  hi2c4.Init.AddressingMode = I2C_ADDRESSINGMODE_7BIT;
  hi2c4.Init.DualAddressMode = I2C_DUALADDRESS_DISABLE;
  hi2c4.Init.OwnAddress2 = 0;
  hi2c4.Init.OwnAddress2Masks = I2C_OA2_NOMASK;
  hi2c4.Init.GeneralCallMode = I2C_GENERALCALL_DISABLE;
  hi2c4.Init.NoStretchMode = I2C_NOSTRETCH_DISABLE;
  if (HAL_I2C_Init(&hi2c4) != HAL_OK)
  {
    Error_Handler();
  }

  /** Configure Analogue filter
  */
  if (HAL_I2CEx_ConfigAnalogFilter(&hi2c4, I2C_ANALOGFILTER_ENABLE) != HAL_OK)
  {
    Error_Handler();
  }

  /** Configure Digital filter
  */
  if (HAL_I2CEx_ConfigDigitalFilter(&hi2c4, 0) != HAL_OK)
  {
    Error_Handler();
  }

}

static void MX_I2S1_Init(void)
{

  hi2s1.Instance = SPI1;
  hi2s1.Init.Mode = I2S_MODE_MASTER_FULLDUPLEX;
  hi2s1.Init.Standard = I2S_STANDARD_PHILIPS;
  hi2s1.Init.DataFormat = I2S_DATAFORMAT_24B;
  hi2s1.Init.MCLKOutput = I2S_MCLKOUTPUT_ENABLE;
  hi2s1.Init.AudioFreq = I2S_AUDIOFREQ_44K;
  hi2s1.Init.CPOL = I2S_CPOL_LOW;
  hi2s1.Init.FirstBit = I2S_FIRSTBIT_MSB;
  hi2s1.Init.WSInversion = I2S_WS_INVERSION_DISABLE;
  hi2s1.Init.Data24BitAlignment = I2S_DATA_24BIT_ALIGNMENT_LEFT;
  hi2s1.Init.MasterKeepIOState = I2S_MASTER_KEEP_IO_STATE_DISABLE;
  if (HAL_I2S_Init(&hi2s1) != HAL_OK)
  {
    Error_Handler();
  }

}

static void MX_SPI2_Init(void)
{

  /* SPI2 parameter configuration*/
  hspi2.Instance = SPI2;
  hspi2.Init.Mode = SPI_MODE_MASTER;
  hspi2.Init.Direction = SPI_DIRECTION_2LINES;
  hspi2.Init.DataSize = SPI_DATASIZE_8BIT;
  hspi2.Init.CLKPolarity = SPI_POLARITY_LOW;
  hspi2.Init.CLKPhase = SPI_PHASE_1EDGE;
  hspi2.Init.NSS = SPI_NSS_SOFT;
  hspi2.Init.BaudRatePrescaler = SPI_BAUDRATEPRESCALER_8;
  hspi2.Init.FirstBit = SPI_FIRSTBIT_MSB;
  hspi2.Init.TIMode = SPI_TIMODE_DISABLE;
  hspi2.Init.CRCCalculation = SPI_CRCCALCULATION_DISABLE;
  hspi2.Init.CRCPolynomial = 0x0;
  hspi2.Init.NSSPMode = SPI_NSS_PULSE_ENABLE;
  hspi2.Init.NSSPolarity = SPI_NSS_POLARITY_LOW;
  hspi2.Init.FifoThreshold = SPI_FIFO_THRESHOLD_01DATA;
  hspi2.Init.TxCRCInitializationPattern = SPI_CRC_INITIALIZATION_ALL_ZERO_PATTERN;
  hspi2.Init.RxCRCInitializationPattern = SPI_CRC_INITIALIZATION_ALL_ZERO_PATTERN;
  hspi2.Init.MasterSSIdleness = SPI_MASTER_SS_IDLENESS_00CYCLE;
  hspi2.Init.MasterInterDataIdleness = SPI_MASTER_INTERDATA_IDLENESS_00CYCLE;
  hspi2.Init.MasterReceiverAutoSusp = SPI_MASTER_RX_AUTOSUSP_DISABLE;
  hspi2.Init.MasterKeepIOState = SPI_MASTER_KEEP_IO_STATE_DISABLE;
  hspi2.Init.IOSwap = SPI_IO_SWAP_DISABLE;
  if (HAL_SPI_Init(&hspi2) != HAL_OK)
  {
    Error_Handler();
  }

}

static void MX_SPI3_Init(void)
{

  /* SPI3 parameter configuration*/
  hspi3.Instance = SPI3;
  hspi3.Init.Mode = SPI_MODE_MASTER;
  hspi3.Init.Direction = SPI_DIRECTION_2LINES;
  hspi3.Init.DataSize = SPI_DATASIZE_8BIT;
  hspi3.Init.CLKPolarity = SPI_POLARITY_LOW;
  hspi3.Init.CLKPhase = SPI_PHASE_1EDGE;
  hspi3.Init.NSS = SPI_NSS_SOFT;
  hspi3.Init.BaudRatePrescaler = SPI_BAUDRATEPRESCALER_8;
  hspi3.Init.FirstBit = SPI_FIRSTBIT_MSB;
  hspi3.Init.TIMode = SPI_TIMODE_DISABLE;
  hspi3.Init.CRCCalculation = SPI_CRCCALCULATION_DISABLE;
  hspi3.Init.CRCPolynomial = 0x0;
  hspi3.Init.NSSPMode = SPI_NSS_PULSE_ENABLE;
  hspi3.Init.NSSPolarity = SPI_NSS_POLARITY_LOW;
  hspi3.Init.FifoThreshold = SPI_FIFO_THRESHOLD_01DATA;
  hspi3.Init.TxCRCInitializationPattern = SPI_CRC_INITIALIZATION_ALL_ZERO_PATTERN;
  hspi3.Init.RxCRCInitializationPattern = SPI_CRC_INITIALIZATION_ALL_ZERO_PATTERN;
  hspi3.Init.MasterSSIdleness = SPI_MASTER_SS_IDLENESS_00CYCLE;
  hspi3.Init.MasterInterDataIdleness = SPI_MASTER_INTERDATA_IDLENESS_00CYCLE;
  hspi3.Init.MasterReceiverAutoSusp = SPI_MASTER_RX_AUTOSUSP_DISABLE;
  hspi3.Init.MasterKeepIOState = SPI_MASTER_KEEP_IO_STATE_DISABLE;
  hspi3.Init.IOSwap = SPI_IO_SWAP_DISABLE;
  if (HAL_SPI_Init(&hspi3) != HAL_OK)
  {
    Error_Handler();
  }

}

static void MX_SPI4_Init(void)
{

  /* SPI4 parameter configuration*/
  hspi4.Instance = SPI4;
  hspi4.Init.Mode = SPI_MODE_SLAVE;
  hspi4.Init.Direction = SPI_DIRECTION_2LINES;
  hspi4.Init.DataSize = SPI_DATASIZE_8BIT;
  hspi4.Init.CLKPolarity = SPI_POLARITY_LOW;
  hspi4.Init.CLKPhase = SPI_PHASE_1EDGE;
  hspi4.Init.NSS = SPI_NSS_SOFT;
  hspi4.Init.FirstBit = SPI_FIRSTBIT_MSB;
  hspi4.Init.TIMode = SPI_TIMODE_DISABLE;
  hspi4.Init.CRCCalculation = SPI_CRCCALCULATION_DISABLE;
  hspi4.Init.CRCPolynomial = 0x0;
  hspi4.Init.NSSPMode = SPI_NSS_PULSE_DISABLE;
  hspi4.Init.NSSPolarity = SPI_NSS_POLARITY_LOW;
  hspi4.Init.FifoThreshold = SPI_FIFO_THRESHOLD_01DATA;
  hspi4.Init.TxCRCInitializationPattern = SPI_CRC_INITIALIZATION_ALL_ZERO_PATTERN;
  hspi4.Init.RxCRCInitializationPattern = SPI_CRC_INITIALIZATION_ALL_ZERO_PATTERN;
  hspi4.Init.MasterSSIdleness = SPI_MASTER_SS_IDLENESS_00CYCLE;
  hspi4.Init.MasterInterDataIdleness = SPI_MASTER_INTERDATA_IDLENESS_00CYCLE;
  hspi4.Init.MasterReceiverAutoSusp = SPI_MASTER_RX_AUTOSUSP_DISABLE;
  hspi4.Init.MasterKeepIOState = SPI_MASTER_KEEP_IO_STATE_DISABLE;
  hspi4.Init.IOSwap = SPI_IO_SWAP_DISABLE;
  if (HAL_SPI_Init(&hspi4) != HAL_OK)
  {
    Error_Handler();
  }

}

static void MX_SPI5_Init(void)
{

  /* SPI5 parameter configuration*/
  hspi5.Instance = SPI5;
  hspi5.Init.Mode = SPI_MODE_MASTER;
  hspi5.Init.Direction = SPI_DIRECTION_2LINES;
  hspi5.Init.DataSize = SPI_DATASIZE_8BIT;
  hspi5.Init.CLKPolarity = SPI_POLARITY_LOW;
  hspi5.Init.CLKPhase = SPI_PHASE_1EDGE;
  hspi5.Init.NSS = SPI_NSS_SOFT;
  hspi5.Init.BaudRatePrescaler = SPI_BAUDRATEPRESCALER_8;
  hspi5.Init.FirstBit = SPI_FIRSTBIT_MSB;
  hspi5.Init.TIMode = SPI_TIMODE_DISABLE;
  hspi5.Init.CRCCalculation = SPI_CRCCALCULATION_DISABLE;
  hspi5.Init.CRCPolynomial = 0x0;
  hspi5.Init.NSSPMode = SPI_NSS_PULSE_ENABLE;
  hspi5.Init.NSSPolarity = SPI_NSS_POLARITY_LOW;
  hspi5.Init.FifoThreshold = SPI_FIFO_THRESHOLD_01DATA;
  hspi5.Init.TxCRCInitializationPattern = SPI_CRC_INITIALIZATION_ALL_ZERO_PATTERN;
  hspi5.Init.RxCRCInitializationPattern = SPI_CRC_INITIALIZATION_ALL_ZERO_PATTERN;
  hspi5.Init.MasterSSIdleness = SPI_MASTER_SS_IDLENESS_00CYCLE;
  hspi5.Init.MasterInterDataIdleness = SPI_MASTER_INTERDATA_IDLENESS_00CYCLE;
  hspi5.Init.MasterReceiverAutoSusp = SPI_MASTER_RX_AUTOSUSP_DISABLE;
  hspi5.Init.MasterKeepIOState = SPI_MASTER_KEEP_IO_STATE_DISABLE;
  hspi5.Init.IOSwap = SPI_IO_SWAP_DISABLE;
  if (HAL_SPI_Init(&hspi5) != HAL_OK)
  {
    Error_Handler();
  }

}

static void MX_SPI6_Init(void)
{

  /* SPI6 parameter configuration*/
  hspi6.Instance = SPI6;
  hspi6.Init.Mode = SPI_MODE_MASTER;
  hspi6.Init.Direction = SPI_DIRECTION_2LINES_TXONLY;
  hspi6.Init.DataSize = SPI_DATASIZE_8BIT;
  hspi6.Init.CLKPolarity = SPI_POLARITY_LOW;
  hspi6.Init.CLKPhase = SPI_PHASE_1EDGE;
  hspi6.Init.NSS = SPI_NSS_SOFT;
  hspi6.Init.BaudRatePrescaler = SPI_BAUDRATEPRESCALER_256;
  hspi6.Init.FirstBit = SPI_FIRSTBIT_MSB;
  hspi6.Init.TIMode = SPI_TIMODE_DISABLE;
  hspi6.Init.CRCCalculation = SPI_CRCCALCULATION_DISABLE;
  hspi6.Init.CRCPolynomial = 0x0;
  hspi6.Init.NSSPMode = SPI_NSS_PULSE_ENABLE;
  hspi6.Init.NSSPolarity = SPI_NSS_POLARITY_LOW;
  hspi6.Init.FifoThreshold = SPI_FIFO_THRESHOLD_01DATA;
  hspi6.Init.TxCRCInitializationPattern = SPI_CRC_INITIALIZATION_ALL_ZERO_PATTERN;
  hspi6.Init.RxCRCInitializationPattern = SPI_CRC_INITIALIZATION_ALL_ZERO_PATTERN;
  hspi6.Init.MasterSSIdleness = SPI_MASTER_SS_IDLENESS_00CYCLE;
  hspi6.Init.MasterInterDataIdleness = SPI_MASTER_INTERDATA_IDLENESS_00CYCLE;
  hspi6.Init.MasterReceiverAutoSusp = SPI_MASTER_RX_AUTOSUSP_DISABLE;
  hspi6.Init.MasterKeepIOState = SPI_MASTER_KEEP_IO_STATE_DISABLE;
  hspi6.Init.IOSwap = SPI_IO_SWAP_DISABLE;
  if (HAL_SPI_Init(&hspi6) != HAL_OK)
  {
    Error_Handler();
  }

}

static void MX_TIM2_Init(void)
{

  TIM_ClockConfigTypeDef sClockSourceConfig = {0};
  TIM_MasterConfigTypeDef sMasterConfig = {0};

  htim2.Instance = TIM2;
  htim2.Init.Prescaler = 240-1;
  htim2.Init.CounterMode = TIM_COUNTERMODE_UP;
  htim2.Init.Period = 1000-1;
  htim2.Init.ClockDivision = TIM_CLOCKDIVISION_DIV1;
  htim2.Init.AutoReloadPreload = TIM_AUTORELOAD_PRELOAD_DISABLE;
  if (HAL_TIM_Base_Init(&htim2) != HAL_OK)
  {
    Error_Handler();
  }
  sClockSourceConfig.ClockSource = TIM_CLOCKSOURCE_INTERNAL;
  if (HAL_TIM_ConfigClockSource(&htim2, &sClockSourceConfig) != HAL_OK)
  {
    Error_Handler();
  }
  sMasterConfig.MasterOutputTrigger = TIM_TRGO_UPDATE;
  sMasterConfig.MasterSlaveMode = TIM_MASTERSLAVEMODE_DISABLE;
  if (HAL_TIMEx_MasterConfigSynchronization(&htim2, &sMasterConfig) != HAL_OK)
  {
    Error_Handler();
  }

}

static void MX_TIM8_Init(void)
{

  TIM_ClockConfigTypeDef sClockSourceConfig = {0};
  TIM_MasterConfigTypeDef sMasterConfig = {0};

  htim8.Instance = TIM8;
  htim8.Init.Prescaler = 240 - 1;
  htim8.Init.CounterMode = TIM_COUNTERMODE_UP;
  htim8.Init.Period = 20-1;
  htim8.Init.ClockDivision = TIM_CLOCKDIVISION_DIV1;
  htim8.Init.RepetitionCounter = 0;
  htim8.Init.AutoReloadPreload = TIM_AUTORELOAD_PRELOAD_DISABLE;
  if (HAL_TIM_Base_Init(&htim8) != HAL_OK)
  {
    Error_Handler();
  }
  sClockSourceConfig.ClockSource = TIM_CLOCKSOURCE_INTERNAL;
  if (HAL_TIM_ConfigClockSource(&htim8, &sClockSourceConfig) != HAL_OK)
  {
    Error_Handler();
  }
  sMasterConfig.MasterOutputTrigger = TIM_TRGO_UPDATE;
  sMasterConfig.MasterOutputTrigger2 = TIM_TRGO2_RESET;
  sMasterConfig.MasterSlaveMode = TIM_MASTERSLAVEMODE_DISABLE;
  if (HAL_TIMEx_MasterConfigSynchronization(&htim8, &sMasterConfig) != HAL_OK)
  {
    Error_Handler();
  }

}

static void MX_TIM15_Init(void)
{

  TIM_ClockConfigTypeDef sClockSourceConfig = {0};
  TIM_MasterConfigTypeDef sMasterConfig = {0};

  htim15.Instance = TIM15;
  htim15.Init.Prescaler = 24000 - 1;
  htim15.Init.CounterMode = TIM_COUNTERMODE_UP;
  htim15.Init.Period = 100 - 1;
  htim15.Init.ClockDivision = TIM_CLOCKDIVISION_DIV1;
  htim15.Init.RepetitionCounter = 0;
  htim15.Init.AutoReloadPreload = TIM_AUTORELOAD_PRELOAD_DISABLE;
  if (HAL_TIM_Base_Init(&htim15) != HAL_OK)
  {
    Error_Handler();
  }
  sClockSourceConfig.ClockSource = TIM_CLOCKSOURCE_INTERNAL;
  if (HAL_TIM_ConfigClockSource(&htim15, &sClockSourceConfig) != HAL_OK)
  {
    Error_Handler();
  }
  sMasterConfig.MasterOutputTrigger = TIM_TRGO_RESET;
  sMasterConfig.MasterSlaveMode = TIM_MASTERSLAVEMODE_DISABLE;
  if (HAL_TIMEx_MasterConfigSynchronization(&htim15, &sMasterConfig) != HAL_OK)
  {
    Error_Handler();
  }

}

static void MX_USB_OTG_FS_PCD_Init(void)
{

  hpcd_USB_OTG_FS.Instance = USB_OTG_FS;
  hpcd_USB_OTG_FS.Init.dev_endpoints = 9;
  hpcd_USB_OTG_FS.Init.speed = PCD_SPEED_FULL;
  hpcd_USB_OTG_FS.Init.dma_enable = DISABLE;
  hpcd_USB_OTG_FS.Init.phy_itface = PCD_PHY_EMBEDDED;
  hpcd_USB_OTG_FS.Init.Sof_enable = DISABLE;
  hpcd_USB_OTG_FS.Init.low_power_enable = DISABLE;
  hpcd_USB_OTG_FS.Init.lpm_enable = DISABLE;
  hpcd_USB_OTG_FS.Init.battery_charging_enable = DISABLE;
  hpcd_USB_OTG_FS.Init.vbus_sensing_enable = DISABLE;
  hpcd_USB_OTG_FS.Init.use_dedicated_ep1 = DISABLE;
  if (HAL_PCD_Init(&hpcd_USB_OTG_FS) != HAL_OK)
  {
    Error_Handler();
  }

}

static void MX_BDMA_Init(void)
{

  /* DMA controller clock enable */
  __HAL_RCC_BDMA_CLK_ENABLE();

  /* DMA interrupt init */
  /* BDMA_Channel0_IRQn interrupt configuration */
  HAL_NVIC_SetPriority(BDMA_Channel0_IRQn, 5, 0);
  HAL_NVIC_EnableIRQ(BDMA_Channel0_IRQn);

}

static void MX_DMA_Init(void)
{

  /* DMA controller clock enable */
  __HAL_RCC_DMA1_CLK_ENABLE();

  /* DMA interrupt init */
  /* DMA1_Stream0_IRQn interrupt configuration */
  HAL_NVIC_SetPriority(DMA1_Stream0_IRQn, 5, 0);
  HAL_NVIC_EnableIRQ(DMA1_Stream0_IRQn);
  /* DMA1_Stream1_IRQn interrupt configuration */
  HAL_NVIC_SetPriority(DMA1_Stream1_IRQn, 5, 0);
  HAL_NVIC_EnableIRQ(DMA1_Stream1_IRQn);
  /* DMA1_Stream2_IRQn interrupt configuration */
  HAL_NVIC_SetPriority(DMA1_Stream2_IRQn, 5, 0);
  HAL_NVIC_EnableIRQ(DMA1_Stream2_IRQn);
  /* DMA1_Stream3_IRQn interrupt configuration */
  HAL_NVIC_SetPriority(DMA1_Stream3_IRQn, 5, 0);
  HAL_NVIC_EnableIRQ(DMA1_Stream3_IRQn);
  /* DMA1_Stream4_IRQn interrupt configuration */
  HAL_NVIC_SetPriority(DMA1_Stream4_IRQn, 5, 0);
  HAL_NVIC_EnableIRQ(DMA1_Stream4_IRQn);
  /* DMA1_Stream5_IRQn interrupt configuration */
  HAL_NVIC_SetPriority(DMA1_Stream5_IRQn, 5, 0);
  HAL_NVIC_EnableIRQ(DMA1_Stream5_IRQn);
  /* DMA1_Stream6_IRQn interrupt configuration */
  HAL_NVIC_SetPriority(DMA1_Stream6_IRQn, 5, 0);
  HAL_NVIC_EnableIRQ(DMA1_Stream6_IRQn);

}

static void MX_GPIO_Init(void)
{
  GPIO_InitTypeDef GPIO_InitStruct = {0};

  /* GPIO Ports Clock Enable */
  __HAL_RCC_GPIOE_CLK_ENABLE();
  __HAL_RCC_GPIOF_CLK_ENABLE();
  __HAL_RCC_GPIOH_CLK_ENABLE();
  __HAL_RCC_GPIOC_CLK_ENABLE();
  __HAL_RCC_GPIOA_CLK_ENABLE();
  __HAL_RCC_GPIOB_CLK_ENABLE();
  __HAL_RCC_GPIOG_CLK_ENABLE();
  __HAL_RCC_GPIOD_CLK_ENABLE();
  __HAL_RCC_GPIOI_CLK_ENABLE();

  /*Configure GPIO pin Output Level */
  HAL_GPIO_WritePin(GPIOF, INTERCONN_RESET_Pin|INTERCONN_REQ_Pin, GPIO_PIN_RESET);

  /*Configure GPIO pin Output Level */
  HAL_GPIO_WritePin(GPIOA, NS_FLASH_CS_4_Pin|EX_HEART_BEAT_Pin, GPIO_PIN_SET);

  /*Configure GPIO pin Output Level */
  HAL_GPIO_WritePin(CODEC_NRST_GPIO_Port, CODEC_NRST_Pin, GPIO_PIN_SET);

  /*Configure GPIO pin Output Level */
  HAL_GPIO_WritePin(NS_FLASH_CS_3_GPIO_Port, NS_FLASH_CS_3_Pin, GPIO_PIN_SET);

  /*Configure GPIO pin Output Level */
  HAL_GPIO_WritePin(GPIOG, STATUS_LED_4_Pin|STATUS_LED_3_Pin, GPIO_PIN_SET);

  /*Configure GPIO pin Output Level */
  HAL_GPIO_WritePin(GPIOE, STATUS_LED_2_Pin|STATUS_LED_1_Pin|NS_FLASH_CS_2_Pin, GPIO_PIN_SET);

  /*Configure GPIO pin Output Level */
  HAL_GPIO_WritePin(NERVE_NET_ACK_GPIO_Port, NERVE_NET_ACK_Pin, GPIO_PIN_RESET);

  /*Configure GPIO pin Output Level */
  HAL_GPIO_WritePin(NS_FLASH_CS_1_GPIO_Port, NS_FLASH_CS_1_Pin, GPIO_PIN_SET);

  /*Configure GPIO pin Output Level */
  HAL_GPIO_WritePin(GPIOD, TIME_MARKER_1_Pin|TIME_MARKER_2_Pin|TIME_MARKER_3_Pin|TIME_MARKER_4_Pin, GPIO_PIN_RESET);

  /*Configure GPIO pin Output Level */
  HAL_GPIO_WritePin(SER_OUT_RCLK_GPIO_Port, SER_OUT_RCLK_Pin, GPIO_PIN_RESET);

  /*Configure GPIO pins : INTERCONN_RESET_Pin INTERCONN_REQ_Pin */
  GPIO_InitStruct.Pin = INTERCONN_RESET_Pin|INTERCONN_REQ_Pin;
  GPIO_InitStruct.Mode = GPIO_MODE_OUTPUT_PP;
  GPIO_InitStruct.Pull = GPIO_PULLUP;
  GPIO_InitStruct.Speed = GPIO_SPEED_FREQ_MEDIUM;
  HAL_GPIO_Init(GPIOF, &GPIO_InitStruct);

  /*Configure GPIO pin : INTERCONN_ACK_Pin */
  GPIO_InitStruct.Pin = INTERCONN_ACK_Pin;
  GPIO_InitStruct.Mode = GPIO_MODE_IT_RISING_FALLING;
  GPIO_InitStruct.Pull = GPIO_NOPULL;
  HAL_GPIO_Init(INTERCONN_ACK_GPIO_Port, &GPIO_InitStruct);

  /*Configure GPIO pin : NS_FLASH_CS_4_Pin */
  GPIO_InitStruct.Pin = NS_FLASH_CS_4_Pin;
  GPIO_InitStruct.Mode = GPIO_MODE_OUTPUT_PP;
  GPIO_InitStruct.Pull = GPIO_NOPULL;
  GPIO_InitStruct.Speed = GPIO_SPEED_FREQ_MEDIUM;
  HAL_GPIO_Init(NS_FLASH_CS_4_GPIO_Port, &GPIO_InitStruct);

  /*Configure GPIO pin : CODEC_NRST_Pin */
  GPIO_InitStruct.Pin = CODEC_NRST_Pin;
  GPIO_InitStruct.Mode = GPIO_MODE_OUTPUT_PP;
  GPIO_InitStruct.Pull = GPIO_PULLUP;
  GPIO_InitStruct.Speed = GPIO_SPEED_FREQ_MEDIUM;
  HAL_GPIO_Init(CODEC_NRST_GPIO_Port, &GPIO_InitStruct);

  /*Configure GPIO pin : NS_FLASH_CS_3_Pin */
  GPIO_InitStruct.Pin = NS_FLASH_CS_3_Pin;
  GPIO_InitStruct.Mode = GPIO_MODE_OUTPUT_PP;
  GPIO_InitStruct.Pull = GPIO_NOPULL;
  GPIO_InitStruct.Speed = GPIO_SPEED_FREQ_MEDIUM;
  HAL_GPIO_Init(NS_FLASH_CS_3_GPIO_Port, &GPIO_InitStruct);

  /*Configure GPIO pins : STATUS_LED_4_Pin STATUS_LED_3_Pin */
  GPIO_InitStruct.Pin = STATUS_LED_4_Pin|STATUS_LED_3_Pin;
  GPIO_InitStruct.Mode = GPIO_MODE_OUTPUT_OD;
  GPIO_InitStruct.Pull = GPIO_NOPULL;
  GPIO_InitStruct.Speed = GPIO_SPEED_FREQ_LOW;
  HAL_GPIO_Init(GPIOG, &GPIO_InitStruct);

  /*Configure GPIO pins : STATUS_LED_2_Pin STATUS_LED_1_Pin */
  GPIO_InitStruct.Pin = STATUS_LED_2_Pin|STATUS_LED_1_Pin;
  GPIO_InitStruct.Mode = GPIO_MODE_OUTPUT_OD;
  GPIO_InitStruct.Pull = GPIO_NOPULL;
  GPIO_InitStruct.Speed = GPIO_SPEED_FREQ_LOW;
  HAL_GPIO_Init(GPIOE, &GPIO_InitStruct);

  /*Configure GPIO pin : NS_FLASH_CS_2_Pin */
  GPIO_InitStruct.Pin = NS_FLASH_CS_2_Pin;
  GPIO_InitStruct.Mode = GPIO_MODE_OUTPUT_PP;
  GPIO_InitStruct.Pull = GPIO_NOPULL;
  GPIO_InitStruct.Speed = GPIO_SPEED_FREQ_MEDIUM;
  HAL_GPIO_Init(NS_FLASH_CS_2_GPIO_Port, &GPIO_InitStruct);

  /*Configure GPIO pins : NERVE_NET_RESET_Pin NERVE_NET_REQ_Pin */
  GPIO_InitStruct.Pin = NERVE_NET_RESET_Pin|NERVE_NET_REQ_Pin;
  GPIO_InitStruct.Mode = GPIO_MODE_IT_RISING_FALLING;
  GPIO_InitStruct.Pull = GPIO_NOPULL;
  HAL_GPIO_Init(GPIOB, &GPIO_InitStruct);

  /*Configure GPIO pins : NERVE_NET_ACK_Pin NS_FLASH_CS_1_Pin */
  GPIO_InitStruct.Pin = NERVE_NET_ACK_Pin|NS_FLASH_CS_1_Pin;
  GPIO_InitStruct.Mode = GPIO_MODE_OUTPUT_PP;
  GPIO_InitStruct.Pull = GPIO_NOPULL;
  GPIO_InitStruct.Speed = GPIO_SPEED_FREQ_MEDIUM;
  HAL_GPIO_Init(GPIOH, &GPIO_InitStruct);

  /*Configure GPIO pin : EX_HEART_BEAT_Pin */
  GPIO_InitStruct.Pin = EX_HEART_BEAT_Pin;
  GPIO_InitStruct.Mode = GPIO_MODE_OUTPUT_OD;
  GPIO_InitStruct.Pull = GPIO_NOPULL;
  GPIO_InitStruct.Speed = GPIO_SPEED_FREQ_LOW;
  HAL_GPIO_Init(EX_HEART_BEAT_GPIO_Port, &GPIO_InitStruct);

  /*Configure GPIO pins : TIME_MARKER_1_Pin TIME_MARKER_2_Pin TIME_MARKER_4_Pin */
  GPIO_InitStruct.Pin = TIME_MARKER_1_Pin|TIME_MARKER_2_Pin|TIME_MARKER_4_Pin;
  GPIO_InitStruct.Mode = GPIO_MODE_OUTPUT_PP;
  GPIO_InitStruct.Pull = GPIO_NOPULL;
  GPIO_InitStruct.Speed = GPIO_SPEED_FREQ_HIGH;
  HAL_GPIO_Init(GPIOD, &GPIO_InitStruct);

  /*Configure GPIO pin : TIME_MARKER_3_Pin */
  GPIO_InitStruct.Pin = TIME_MARKER_3_Pin;
  GPIO_InitStruct.Mode = GPIO_MODE_OUTPUT_PP;
  GPIO_InitStruct.Pull = GPIO_NOPULL;
  GPIO_InitStruct.Speed = GPIO_SPEED_FREQ_LOW;
  HAL_GPIO_Init(TIME_MARKER_3_GPIO_Port, &GPIO_InitStruct);

  /*Configure GPIO pin : SER_OUT_RCLK_Pin */
  GPIO_InitStruct.Pin = SER_OUT_RCLK_Pin;
  GPIO_InitStruct.Mode = GPIO_MODE_OUTPUT_PP;
  GPIO_InitStruct.Pull = GPIO_NOPULL;
  GPIO_InitStruct.Speed = GPIO_SPEED_FREQ_LOW;
  HAL_GPIO_Init(SER_OUT_RCLK_GPIO_Port, &GPIO_InitStruct);

  /* EXTI interrupt init*/
  HAL_NVIC_SetPriority(INTERCONN_ACK_EXTI_IRQn, 5, 0);
  HAL_NVIC_EnableIRQ(INTERCONN_ACK_EXTI_IRQn);

  HAL_NVIC_SetPriority(NERVE_NET_RESET_EXTI_IRQn, 5, 0);
  HAL_NVIC_EnableIRQ(NERVE_NET_RESET_EXTI_IRQn);

}

void StartDefaultTask(void *argument)
{
  /* USER CODE BEGIN 5 */

	// Sweep the status led's as a sign of live...
	displayStatus((eStatusCodes)0x01);
	osDelay(100);
	displayStatus((eStatusCodes)0x02);
	osDelay(100);
	displayStatus((eStatusCodes)0x04);
	osDelay(100);
	displayStatus((eStatusCodes)0x08);
	osDelay(100);
	displayStatus(scStartingUp);

    // Get the amount of free heap memory
    size_t xFreeHeapSize = xPortGetFreeHeapSize();
    UNUSED(xFreeHeapSize);

    // Create a trigger thread to toggle TimeMarker_1
	TaskHandle_t xHandle;
	BaseType_t res = xTaskCreate ( CasualNoises::TriggerThread, "TriggerThread", 32, nullptr,
			TRIGGER_THREAD_PRIORITY, &xHandle );

	// Get a I2S driver for the CS4270
	static CasualNoises::CS4270_DriverParams codecParams;
	codecParams.codecResetPort 	= CODEC_NRST_GPIO_Port;
	codecParams.codecResetPin	= CODEC_NRST_Pin;
	codecParams.hi2cHandle		= &hi2c4;
	CasualNoises::Codec_Driver& codecDriverPtr = CasualNoises::CS4270_Driver::CreateDriver ( codecParams );
	HAL_StatusTypeDef success = codecDriverPtr.initializeCodec();
	if (success != HAL_OK)
		CN_ReportFault(eErrorCodes::CS4270_DriverError);

	// Synthesizer engine parameters & default settings
	CasualNoises::tSynthEngineParams synthEngineParams;
	memset(&synthEngineParams, 0, sizeof(CasualNoises::tSynthEngineParams));
	synthEngineParams.frequency = 110.0;
	synthEngineParams.bmp		= 60.0;

	// Create an engine thread and run it
	// Note, part of the sNorthSideEngineParams is filled in by the UI thread when starting up
	void ( *nerveNetCallBackPtr ) ( CasualNoises::sNerveNetData* ) = nullptr;
	static CasualNoises::sNorthSideEngineParams engineParams;
	// ... NVM Driver settings
	engineParams.nvmDriverInitData.noOfDevices				= 4;
	engineParams.nvmDriverInitData.hspix_ptr				= &hspi2;
	engineParams.nvmDriverInitData.deviceSelectPorts[0]		= NS_FLASH_CS_1_GPIO_Port;
	engineParams.nvmDriverInitData.deviceSelectPins[0]		= NS_FLASH_CS_1_Pin;
	engineParams.nvmDriverInitData.deviceSelectPorts[1]		= NS_FLASH_CS_2_GPIO_Port;
	engineParams.nvmDriverInitData.deviceSelectPins[1]		= NS_FLASH_CS_2_Pin;
	engineParams.nvmDriverInitData.deviceSelectPorts[2]		= NS_FLASH_CS_3_GPIO_Port;
	engineParams.nvmDriverInitData.deviceSelectPins[2]		= NS_FLASH_CS_3_Pin;
	engineParams.nvmDriverInitData.deviceSelectPorts[3]		= NS_FLASH_CS_4_GPIO_Port;
	engineParams.nvmDriverInitData.deviceSelectPins[3]		= NS_FLASH_CS_4_Pin;
	// ... NerveNet data call back handler
	engineParams.nerveNetCallBackPtr   						= &nerveNetCallBackPtr;
	// Start North Side engine thread
	res = CasualNoises::StartNorthSideEngineThread ( &engineParams );
	if (res != pdPASS)
		CN_ReportFault(eErrorCodes::FreeRTOS_ErrorRes);

	// Wait until engine thread is running
	while ( ! CasualNoises::gYellowPages.gEngineThreadRunning )
		vTaskDelay ( pdMS_TO_TICKS ( 10 ) );

	// Start event handler thread
	CasualNoises::EventHandlerThread::sEventHandlerThreadData eventHandlerData;
	eventHandlerData.TimerHandle 			= &htim15;
	eventHandlerData.SynthEngineParamsPtr	= &synthEngineParams;
	res = CasualNoises::EventHandlerThread::StartEventHandlerThread(&eventHandlerData);
	if (res != pdPASS)
		CN_ReportFault(eErrorCodes::FreeRTOS_ErrorRes);

	// Create an audio thread and run it
	CasualNoises::NorthSideAudioProcessor* audioProcessorPtr = CasualNoises::NorthSideAudioProcessor::getNorthSideAudioProcessor ();
	static CasualNoises::sAudioThreadInitData audioData;
	audioData.audioProcessorPtr		= audioProcessorPtr;
	audioData.hi2sHandlePtr 		= &hi2s1;
	audioData.nerveNetCallBackPtr   = engineParams.nerveNetCallBackPtr;
	CasualNoises::StartAudioThread ( &audioData );

	// Create an ADC handler thread - CV inputs are also handled by the South Side
	TaskHandle_t xADC_ThreadHandle;
	CasualNoises::sADC_ThreadData ADC_ThreadData;
	ADC_ThreadData.hadc					= &hadc1;
	ADC_ThreadData.htim 				= &htim8;
	ADC_ThreadData.ADC_DataHandlerPtr	= audioProcessorPtr;
	res = CasualNoises::startADC_Thread((void *)&ADC_ThreadData, &xADC_ThreadHandle);
	if (res != pdPASS)
		CN_ReportFault(eErrorCodes::UI_ThreadError);

	// There are no NerveNet threads running
	for (uint32_t i = 0; i < MAX_NO_OF_NERVENET_MASTER_THREADS; ++i)
		gNerveNetMasterThreadPtr[i] = nullptr;
	for (uint32_t i = 0; i < MAX_NO_OF_NERVENET_SLAVE_THREADS; ++i)
		gNerveNetSlaveThreadPtr[i] = nullptr;

	// Start NerveNet master thread to interact with the South Side
	static CasualNoises::sNerveNetThreadData nerveNetMasterThreadData;
	memset ( &nerveNetMasterThreadData, 0x00, sizeof ( CasualNoises::sNerveNetThreadData ) );
	nerveNetMasterThreadData.NerveNetThreadNo		= 0;
	nerveNetMasterThreadData.NerveNet_REQ_Port		= INTERCONN_REQ_GPIO_Port;
	nerveNetMasterThreadData.NerveNet_REQ_Pin		= INTERCONN_REQ_Pin;
	nerveNetMasterThreadData.NerveNet_ACK_Port		= INTERCONN_ACK_GPIO_Port;
	nerveNetMasterThreadData.NerveNet_ACK_Pin		= INTERCONN_ACK_Pin;
	nerveNetMasterThreadData.NerveNet_RESET_Port	= INTERCONN_RESET_GPIO_Port;
	nerveNetMasterThreadData.NerveNet_RESET_Pin		= INTERCONN_RESET_Pin;
	nerveNetMasterThreadData.NerveNet_SPI_Ptr		= &hspi5;
	nerveNetMasterThreadData.NerveNetThreadQueue	= &CasualNoises::gYellowPages.gNerveNetMasterThreadQueueHandle;
	nerveNetMasterThreadData.NerveNetRunningFlagPtr	= &CasualNoises::gYellowPages.gNetMasterThreadRunning;
	static TaskHandle_t xMasterHandlePtr;
	static CasualNoises::NerveNetMasterThread nerveNetMasterThread;
	res = CasualNoises::startNerveNetMasterThread ( &nerveNetMasterThread, &nerveNetMasterThreadData, &xMasterHandlePtr );
	if ( res != pdPASS )
		CN_ReportFault ( eErrorCodes::NerveNetThread_Error );
	CasualNoises::gYellowPages.gNerveNetMasterThreadTaskHandle 	= xMasterHandlePtr;

	// Start NerveNet slave thread to interact with the Device Board
	static CasualNoises::sNerveNetThreadData nerveNetSlaveThreadData;
	memset ( &nerveNetSlaveThreadData, 0x00, sizeof ( CasualNoises::sNerveNetThreadData ) );
	nerveNetSlaveThreadData.NerveNetThreadNo		= 0;
	nerveNetSlaveThreadData.NerveNet_REQ_Port		= NERVE_NET_REQ_GPIO_Port;
	nerveNetSlaveThreadData.NerveNet_REQ_Pin		= NERVE_NET_REQ_Pin;
	nerveNetSlaveThreadData.NerveNet_ACK_Port		= NERVE_NET_ACK_GPIO_Port;
	nerveNetSlaveThreadData.NerveNet_ACK_Pin		= NERVE_NET_ACK_Pin;
	nerveNetSlaveThreadData.NerveNet_RESET_Port		= NERVE_NET_RESET_GPIO_Port;
	nerveNetSlaveThreadData.NerveNet_RESET_Pin		= NERVE_NET_RESET_Pin;
	nerveNetSlaveThreadData.NerveNet_SPI_Ptr		= &hspi4;
	nerveNetSlaveThreadData.NerveNetThreadQueue		= &CasualNoises::gYellowPages.gNerveNetSlaveThreadQueueHandle;
	nerveNetSlaveThreadData.NerveNetRunningFlagPtr	= &CasualNoises::gYellowPages.gNetSlaveThreadRunning;
	static TaskHandle_t xSlaveHandlePtr;
	static CasualNoises::NerveNetSlaveThread nerveNetSlaveThread;
	res = CasualNoises::startNerveNetSlaveThread ( &nerveNetSlaveThread, &nerveNetSlaveThreadData, &xSlaveHandlePtr );
	if ( res != pdPASS )
		CN_ReportFault ( eErrorCodes::NerveNetThread_Error );
	CasualNoises::gYellowPages.gNerveNetSlaveThreadTaskHandle 	= xSlaveHandlePtr;
	CasualNoises::DeviceBoardConnection deviceBoardConnection;
	gNerveNetSlaveThreadPtr [ nerveNetSlaveThreadData.NerveNetThreadNo ]->setNerveNetSlaveProcessorPtr( &deviceBoardConnection );

	/* Infinite loop */
	osDelay ( pdMS_TO_TICKS ( 200 ) );
	displayStatus ( scRunning );
	for(;;)
	{
		HAL_GPIO_WritePin ( EX_HEART_BEAT_GPIO_Port, EX_HEART_BEAT_Pin, GPIO_PIN_RESET );
		osDelay( pdMS_TO_TICKS ( 100 ) );
		HAL_GPIO_WritePin( EX_HEART_BEAT_GPIO_Port, EX_HEART_BEAT_Pin, GPIO_PIN_SET );
		osDelay( pdMS_TO_TICKS ( 100 ) );
		HAL_GPIO_WritePin ( EX_HEART_BEAT_GPIO_Port, EX_HEART_BEAT_Pin, GPIO_PIN_RESET );
		osDelay ( pdMS_TO_TICKS ( 100 ) );
		HAL_GPIO_WritePin ( EX_HEART_BEAT_GPIO_Port, EX_HEART_BEAT_Pin, GPIO_PIN_SET );
		osDelay ( pdMS_TO_TICKS ( 700 ) );
	}
  /* USER CODE END 5 */
}

 /* MPU Configuration */

void MPU_Config(void)
{
  MPU_Region_InitTypeDef MPU_InitStruct = {0};

  /* Disables the MPU */
  HAL_MPU_Disable();

  /** Initializes and configures the Region and the memory to be protected
  */
  MPU_InitStruct.Enable = MPU_REGION_ENABLE;
  MPU_InitStruct.Number = MPU_REGION_NUMBER0;
  MPU_InitStruct.BaseAddress = 0x30000000;
  MPU_InitStruct.Size = MPU_REGION_SIZE_256KB;
  MPU_InitStruct.SubRegionDisable = 0x87;
  MPU_InitStruct.TypeExtField = MPU_TEX_LEVEL0;
  MPU_InitStruct.AccessPermission = MPU_REGION_FULL_ACCESS;
  MPU_InitStruct.DisableExec = MPU_INSTRUCTION_ACCESS_DISABLE;
  MPU_InitStruct.IsShareable = MPU_ACCESS_SHAREABLE;
  MPU_InitStruct.IsCacheable = MPU_ACCESS_NOT_CACHEABLE;
  MPU_InitStruct.IsBufferable = MPU_ACCESS_NOT_BUFFERABLE;

  HAL_MPU_ConfigRegion(&MPU_InitStruct);
  /* Enables the MPU */
  HAL_MPU_Enable(MPU_PRIVILEGED_DEFAULT);

}

void HAL_TIM_PeriodElapsedCallback(TIM_HandleTypeDef *htim)
{
  /* USER CODE BEGIN Callback 0 */

  if (htim->Instance == TIM15)
  {
	  CasualNoises::EventHandlerThread::eventHandlerTimerInterrupts();
  }

  /* USER CODE END Callback 0 */
  if (htim->Instance == TIM1)
  {
    HAL_IncTick();
  }
}

void Error_Handler(void)
{
  __disable_irq();
  while (1)
  {
  }
}
